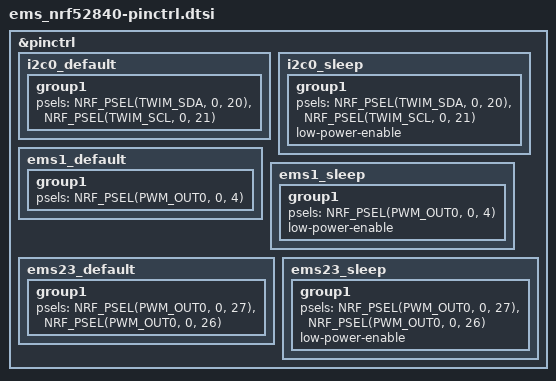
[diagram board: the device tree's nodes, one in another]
&pinctrl {
	i2c0_default: i2c0_default {
		group1 {
			psels = <NRF_PSEL(TWIM_SDA, 0, 20)>,
				<NRF_PSEL(TWIM_SCL, 0, 21)>;
		};
	};

	i2c0_sleep: i2c0_sleep {
		group1 {
			psels = <NRF_PSEL(TWIM_SDA, 0, 20)>,
				<NRF_PSEL(TWIM_SCL, 0, 21)>;
			low-power-enable;
		};
	};

	// Chan1, 
	// Note: this is for compatibility purposes, pin selection done in ems_pwm.c
	ems1_default: ems1_default {
		group1 {
			psels = <NRF_PSEL(PWM_OUT0, 0, 4)>;
		};
	};

	// Chan1, 
	// Note: this is for compatibility purposes, pin selection done in ems_pwm.c
	ems1_sleep: ems1_sleep {
		group1 {
			psels = <NRF_PSEL(PWM_OUT0, 0, 4)>;
			low-power-enable;
		};
	};

	// Chan 2, 3 
	// Note: this is for compatibility purposes, pin selection done in ems_pwm.c
	ems23_default: ems23_default {
		group1 {
			psels = <NRF_PSEL(PWM_OUT0, 0, 27)>, <NRF_PSEL(PWM_OUT0, 0, 26)>;
		};
	};

	// Chan 2, 3 
	// Note: this is for compatibility purposes, pin selection done in ems_pwm.c
	ems23_sleep: ems23_sleep {
		group1 {
			psels = <NRF_PSEL(PWM_OUT0, 0, 27)>, <NRF_PSEL(PWM_OUT0, 0, 26)>;
			low-power-enable;
		};
	};
};
